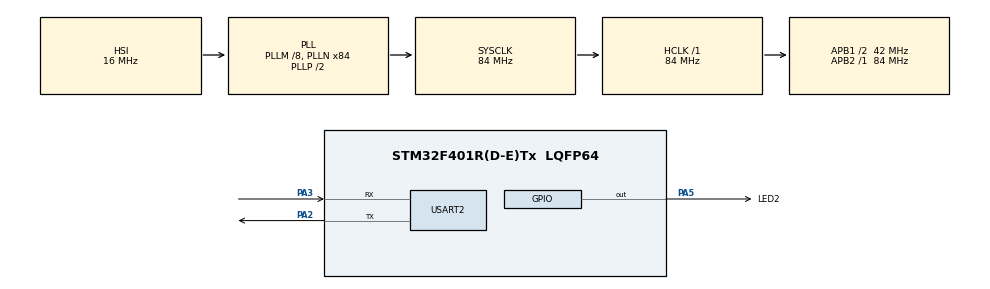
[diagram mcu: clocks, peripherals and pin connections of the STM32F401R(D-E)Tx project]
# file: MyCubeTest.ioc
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FREERTOS.Tasks01=MyLedTask,0,128,LedTask,Default,NULL,Dynamic,NULL,NULL;myUsartTask,-3,128,UsartTask,Default,NULL,Dynamic,NULL,NULL
Mcu.Family=STM32F4
Mcu.Name=STM32F401R(D-E)Tx
Mcu.Package=LQFP64
NVIC.PriorityGroup=NVIC_PRIORITYGROUP_4
NVIC.TIM5_IRQn=true\:0\:0\:false\:false\:true\:false\:false
NVIC.TimeBase=TIM5_IRQn
NVIC.TimeBaseIP=TIM5
NVIC.USART2_IRQn=true\:5\:0\:false\:false\:true\:true\:true
PA2.Mode=Asynchronous
PA2.Signal=USART2_TX
PA3.Mode=Asynchronous
PA3.Signal=USART2_RX
PA5.GPIO_Label=LED2
PA5.Signal=GPIO_Output
ProjectManager.HeapSize=0x200
ProjectManager.StackSize=0x400
ProjectManager.TargetToolchain=MDK-ARM V5
RCC.48MHZClocksFreq_Value=42000000
RCC.AHBFreq_Value=84000000
RCC.APB1CLKDivider=RCC_HCLK_DIV2
RCC.APB1Freq_Value=42000000
RCC.APB1TimFreq_Value=84000000
RCC.APB2Freq_Value=84000000
RCC.APB2TimFreq_Value=84000000
RCC.CortexFreq_Value=84000000
RCC.HCLKFreq_Value=84000000
RCC.HSE_VALUE=4000000
RCC.HSI_VALUE=16000000
RCC.LSE_VALUE=32768
RCC.PLLM=8
RCC.PLLN=84
RCC.SYSCLKFreq_VALUE=84000000
RCC.SYSCLKSource=RCC_SYSCLKSOURCE_PLLCLK
RCC.VCOOutputFreq_Value=168000000
USART2.VirtualMode=VM_ASYNC
VP_FREERTOS_VS_ENABLE.Mode=Enabled
VP_SYS_VS_tim5.Mode=TIM5
board=MyCubeTest

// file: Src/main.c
/**
  ******************************************************************************
  * @file           : main.c
  * @brief          : Main program body
  ******************************************************************************
  * This notice applies to any and all portions of this file
  * that are not between comment pairs USER CODE BEGIN and
  * USER CODE END. Other portions of this file, whether
  * inserted by the user or by software development tools
  * are owned by their respective copyright owners.
  *
  * Copyright (c) 2018 STMicroelectronics International N.V.
  * All rights reserved.
  *
  * Redistribution and use in source and binary forms, with or without
  * modification, are permitted, provided that the following conditions are met:
  *
  * 1. Redistribution of source code must retain the above copyright notice,
  *    this list of conditions and the following disclaimer.
  * 2. Redistributions in binary form must reproduce the above copyright notice,
  *    this list of conditions and the following disclaimer in the documentation
  *    and/or other materials provided with the distribution.
  * 3. Neither the name of STMicroelectronics nor the names of other
  *    contributors to this software may be used to endorse or promote products
  *    derived from this software without specific written permission.
  * 4. This software, including modifications and/or derivative works of this
  *    software, must execute solely and exclusively on microcontroller or
  *    microprocessor devices manufactured by or for STMicroelectronics.
  * 5. Redistribution and use of this software other than as permitted under
  *    this license is void and will automatically terminate your rights under
  *    this license.
  *
  * THIS SOFTWARE IS PROVIDED BY STMICROELECTRONICS AND CONTRIBUTORS "AS IS"
  * AND ANY EXPRESS, IMPLIED OR STATUTORY WARRANTIES, INCLUDING, BUT NOT
  * LIMITED TO, THE IMPLIED WARRANTIES OF MERCHANTABILITY, FITNESS FOR A
  * PARTICULAR PURPOSE AND NON-INFRINGEMENT OF THIRD PARTY INTELLECTUAL PROPERTY
  * RIGHTS ARE DISCLAIMED TO THE FULLEST EXTENT PERMITTED BY LAW. IN NO EVENT
  * SHALL STMICROELECTRONICS OR CONTRIBUTORS BE LIABLE FOR ANY DIRECT, INDIRECT,
  * INCIDENTAL, SPECIAL, EXEMPLARY, OR CONSEQUENTIAL DAMAGES (INCLUDING, BUT NOT
  * LIMITED TO, PROCUREMENT OF SUBSTITUTE GOODS OR SERVICES; LOSS OF USE, DATA,
  * OR PROFITS; OR BUSINESS INTERRUPTION) HOWEVER CAUSED AND ON ANY THEORY OF
  * LIABILITY, WHETHER IN CONTRACT, STRICT LIABILITY, OR TORT (INCLUDING
  * NEGLIGENCE OR OTHERWISE) ARISING IN ANY WAY OUT OF THE USE OF THIS SOFTWARE,
  * EVEN IF ADVISED OF THE POSSIBILITY OF SUCH DAMAGE.
  *
  ******************************************************************************
  */
#include "main.h"
#include "stm32f4xx_hal.h"
#include "cmsis_os.h"
#include "usart.h"
#include "gpio.h"

/* USER CODE BEGIN PV */
/* Private variables ---------------------------------------------------------*/
uint8_t aRxBuffer[20];
/* USER CODE END PV */

void SystemClock_Config(void);
void MX_FREERTOS_Init(void);

/* USER CODE BEGIN PFP */
/* Private function prototypes -----------------------------------------------*/

/* USER CODE END PFP */

int main(void)
{

  /* MCU Configuration----------------------------------------------------------*/

  /* Reset of all peripherals, Initializes the Flash interface and the Systick. */
  HAL_Init();

  /* Configure the system clock */
  SystemClock_Config();

  /* Initialize all configured peripherals */
  MX_GPIO_Init();
  MX_USART2_UART_Init();
  /* USER CODE BEGIN 2 */
	HAL_UART_Receive_IT(&huart2, (uint8_t *)aRxBuffer, 10);
  /* USER CODE END 2 */

  /* Call init function for freertos objects (in freertos.c) */
  MX_FREERTOS_Init();

  /* Start scheduler */
  osKernelStart();

  /* We should never get here as control is now taken by the scheduler */

  /* Infinite loop */
  while (1)
  {

  }

}

void SystemClock_Config(void)
{

  RCC_OscInitTypeDef RCC_OscInitStruct;
  RCC_ClkInitTypeDef RCC_ClkInitStruct;

    /**Configure the main internal regulator output voltage
    */
  __HAL_RCC_PWR_CLK_ENABLE();

  __HAL_PWR_VOLTAGESCALING_CONFIG(PWR_REGULATOR_VOLTAGE_SCALE2);

    /**Initializes the CPU, AHB and APB busses clocks
    */
  RCC_OscInitStruct.OscillatorType = RCC_OSCILLATORTYPE_HSI;
  RCC_OscInitStruct.HSIState = RCC_HSI_ON;
  RCC_OscInitStruct.HSICalibrationValue = 16;
  RCC_OscInitStruct.PLL.PLLState = RCC_PLL_ON;
  RCC_OscInitStruct.PLL.PLLSource = RCC_PLLSOURCE_HSI;
  RCC_OscInitStruct.PLL.PLLM = 8;
  RCC_OscInitStruct.PLL.PLLN = 84;
  RCC_OscInitStruct.PLL.PLLP = RCC_PLLP_DIV2;
  RCC_OscInitStruct.PLL.PLLQ = 4;
  if (HAL_RCC_OscConfig(&RCC_OscInitStruct) != HAL_OK)
  {
    _Error_Handler(__FILE__, __LINE__);
  }

    /**Initializes the CPU, AHB and APB busses clocks
    */
  RCC_ClkInitStruct.ClockType = RCC_CLOCKTYPE_HCLK|RCC_CLOCKTYPE_SYSCLK
                              |RCC_CLOCKTYPE_PCLK1|RCC_CLOCKTYPE_PCLK2;
  RCC_ClkInitStruct.SYSCLKSource = RCC_SYSCLKSOURCE_PLLCLK;
  RCC_ClkInitStruct.AHBCLKDivider = RCC_SYSCLK_DIV1;
  RCC_ClkInitStruct.APB1CLKDivider = RCC_HCLK_DIV2;
  RCC_ClkInitStruct.APB2CLKDivider = RCC_HCLK_DIV1;

  if (HAL_RCC_ClockConfig(&RCC_ClkInitStruct, FLASH_LATENCY_2) != HAL_OK)
  {
    _Error_Handler(__FILE__, __LINE__);
  }

    /**Configure the Systick interrupt time
    */
  HAL_SYSTICK_Config(HAL_RCC_GetHCLKFreq()/1000);

    /**Configure the Systick
    */
  HAL_SYSTICK_CLKSourceConfig(SYSTICK_CLKSOURCE_HCLK);

  /* SysTick_IRQn interrupt configuration */
  HAL_NVIC_SetPriority(SysTick_IRQn, 15, 0);
}

void HAL_TIM_PeriodElapsedCallback(TIM_HandleTypeDef *htim)
{
  if (htim->Instance == TIM5) {
    HAL_IncTick();
  }
}

void _Error_Handler(char *file, int line)
{
  while(1)
  {
  }
}

void HAL_UART_RxCpltCallback(UART_HandleTypeDef *huart)
{
  /* Prevent unused argument(s) compilation warning */
  UNUSED(huart);
  /* NOTE : This function should not be modified, when the callback is needed,
            the HAL_UART_RxCpltCallback can be implemented in the user file
   */
  HAL_UART_Transmit(&huart2, (uint8_t *)aRxBuffer, 10,0xFFFF);
}

/************************ (C) COPYRIGHT STMicroelectronics *****END OF FILE****/

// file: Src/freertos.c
/**
  ******************************************************************************
  * File Name          : freertos.c
  * Description        : Code for freertos applications
  ******************************************************************************
  * This notice applies to any and all portions of this file
  * that are not between comment pairs USER CODE BEGIN and
  * USER CODE END. Other portions of this file, whether
  * inserted by the user or by software development tools
  * are owned by their respective copyright owners.
  *
  * Copyright (c) 2018 STMicroelectronics International N.V.
  * All rights reserved.
  *
  * Redistribution and use in source and binary forms, with or without
  * modification, are permitted, provided that the following conditions are met:
  *
  * 1. Redistribution of source code must retain the above copyright notice,
  *    this list of conditions and the following disclaimer.
  * 2. Redistributions in binary form must reproduce the above copyright notice,
  *    this list of conditions and the following disclaimer in the documentation
  *    and/or other materials provided with the distribution.
  * 3. Neither the name of STMicroelectronics nor the names of other
  *    contributors to this software may be used to endorse or promote products
  *    derived from this software without specific written permission.
  * 4. This software, including modifications and/or derivative works of this
  *    software, must execute solely and exclusively on microcontroller or
  *    microprocessor devices manufactured by or for STMicroelectronics.
  * 5. Redistribution and use of this software other than as permitted under
  *    this license is void and will automatically terminate your rights under
  *    this license.
  *
  * THIS SOFTWARE IS PROVIDED BY STMICROELECTRONICS AND CONTRIBUTORS "AS IS"
  * AND ANY EXPRESS, IMPLIED OR STATUTORY WARRANTIES, INCLUDING, BUT NOT
  * LIMITED TO, THE IMPLIED WARRANTIES OF MERCHANTABILITY, FITNESS FOR A
  * PARTICULAR PURPOSE AND NON-INFRINGEMENT OF THIRD PARTY INTELLECTUAL PROPERTY
  * RIGHTS ARE DISCLAIMED TO THE FULLEST EXTENT PERMITTED BY LAW. IN NO EVENT
  * SHALL STMICROELECTRONICS OR CONTRIBUTORS BE LIABLE FOR ANY DIRECT, INDIRECT,
  * INCIDENTAL, SPECIAL, EXEMPLARY, OR CONSEQUENTIAL DAMAGES (INCLUDING, BUT NOT
  * LIMITED TO, PROCUREMENT OF SUBSTITUTE GOODS OR SERVICES; LOSS OF USE, DATA,
  * OR PROFITS; OR BUSINESS INTERRUPTION) HOWEVER CAUSED AND ON ANY THEORY OF
  * LIABILITY, WHETHER IN CONTRACT, STRICT LIABILITY, OR TORT (INCLUDING
  * NEGLIGENCE OR OTHERWISE) ARISING IN ANY WAY OUT OF THE USE OF THIS SOFTWARE,
  * EVEN IF ADVISED OF THE POSSIBILITY OF SUCH DAMAGE.
  *
  ******************************************************************************
  */

#include "FreeRTOS.h"
#include "task.h"
#include "cmsis_os.h"

/* USER CODE BEGIN Includes */
#include "gpio.h"
/* USER CODE END Includes */

osThreadId MyLedTaskHandle;

void LedTask(void const * argument);

void MX_FREERTOS_Init(void); /* (MISRA C 2004 rule 8.1) */

/* Hook prototypes */

/* Init FreeRTOS */

void MX_FREERTOS_Init(void) {

  /* Create the thread(s) */
  /* definition and creation of MyLedTask */
  osThreadDef(MyLedTask, LedTask, osPriorityNormal, 0, 128);
  MyLedTaskHandle = osThreadCreate(osThread(MyLedTask), NULL);

}

/* LedTask function */
void LedTask(void const * argument)
{

  /* USER CODE BEGIN LedTask */
  /* Infinite loop */
  for(;;)
  {
		HAL_GPIO_TogglePin(LED2_GPIO_Port,LED2_Pin);
    osDelay(100);
  }
  /* USER CODE END LedTask */
}

/************************ (C) COPYRIGHT STMicroelectronics *****END OF FILE****/
